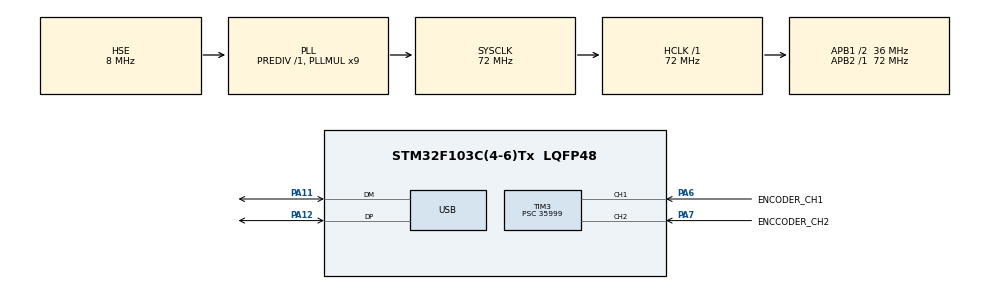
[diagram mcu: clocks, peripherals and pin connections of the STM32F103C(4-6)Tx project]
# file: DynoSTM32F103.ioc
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Mcu.Family=STM32F1
Mcu.Name=STM32F103C(4-6)Tx
Mcu.Package=LQFP48
NVIC.PriorityGroup=NVIC_PRIORITYGROUP_4
NVIC.TIM2_IRQn=true\:0\:0\:false\:true\:true\:3\:true\:true\:true
NVIC.TIM3_IRQn=true\:0\:0\:false\:true\:true\:1\:true\:true\:true
NVIC.USB_LP_CAN1_RX0_IRQn=true\:0\:0\:false\:true\:true\:2\:true\:true\:true
PA11.Mode=Device
PA11.Signal=USB_DM
PA12.Mode=Device
PA12.Signal=USB_DP
PA6.GPIO_Label=ENCODER_CH1
PA6.Signal=S_TIM3_CH1
PA7.GPIO_Label=ENCCODER_CH2
PA7.Signal=S_TIM3_CH2
PD0-OSC_IN.Mode=HSE-External-Oscillator
PD0-OSC_IN.Signal=RCC_OSC_IN
PD1-OSC_OUT.Mode=HSE-External-Oscillator
PD1-OSC_OUT.Signal=RCC_OSC_OUT
ProjectManager.HeapSize=0x200
ProjectManager.StackSize=0x400
ProjectManager.TargetToolchain=STM32CubeIDE
RCC.AHBFreq_Value=72000000
RCC.APB1CLKDivider=RCC_HCLK_DIV2
RCC.APB1Freq_Value=36000000
RCC.APB1TimFreq_Value=72000000
RCC.APB2Freq_Value=72000000
RCC.APB2TimFreq_Value=72000000
RCC.HCLKFreq_Value=72000000
RCC.PLLMUL=RCC_PLL_MUL9
RCC.SYSCLKFreq_VALUE=72000000
RCC.SYSCLKSource=RCC_SYSCLKSOURCE_PLLCLK
RCC.USBFreq_Value=48000000
RCC.USBPrescaler=RCC_USBCLKSOURCE_PLL_DIV1_5
SH.S_TIM3_CH1.0=TIM3_CH1,Encoder_Interface
SH.S_TIM3_CH2.0=TIM3_CH2,Encoder_Interface
TIM2.Period=999
TIM2.Prescaler=35999
TIM3.AutoReloadPreload=TIM_AUTORELOAD_PRELOAD_DISABLE
TIM3.IC1Prescaler=TIM_ICPSC_DIV1
TIM3.Period=3999
TIM3.Prescaler=35999
USB_DEVICE.APP_RX_DATA_SIZE=512
USB_DEVICE.APP_TX_DATA_SIZE=512
USB_DEVICE.CLASS_NAME_FS=CDC
USB_DEVICE.CONFIGURATION_STRING_CDC_FS=CDC_Config
USB_DEVICE.INTERFACE_STRING_CDC_FS=CDC_Interface
USB_DEVICE.MANUFACTURER_STRING=PolijeTI
USB_DEVICE.PID_CDC_FS=1406
USB_DEVICE.PRODUCT_STRING_CDC_FS=DynoTest_Polije
USB_DEVICE.VID=3220
USB_DEVICE.VirtualMode=Cdc
USB_DEVICE.VirtualModeFS=Cdc_FS
VP_TIM2_VS_ClockSourceINT.Mode=Internal
VP_USB_DEVICE_VS_USB_DEVICE_CDC_FS.Mode=CDC_FS
board=custom

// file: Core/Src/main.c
/* USER CODE BEGIN Header */
/**
 ******************************************************************************
 * @file           : main.c
 * @brief          : Main program body
 ******************************************************************************
 * @attention
 *
 * Copyright (c) 2023 STMicroelectronics.
 * All rights reserved.
 *
 * This software is licensed under terms that can be found in the LICENSE file
 * in the root directory of this software component.
 * If no LICENSE file comes with this software, it is provided AS-IS.
 *
 ******************************************************************************
 */
/* USER CODE END Header */
#include <gpio.h>
#include <main.h>
#include <tim.h>
#include <usb_device.h>

void SystemClock_Config(void);
static void MX_NVIC_Init(void);

int main(void) {

  /* MCU Configuration--------------------------------------------------------*/

  /* Reset of all peripherals, Initializes the Flash interface and the Systick.
   */
  HAL_Init();

  /* Configure the system clock */
  SystemClock_Config();

  /* Initialize all configured peripherals */
  MX_GPIO_Init();
  MX_TIM2_Init();
  MX_TIM3_Init();
  MX_USB_DEVICE_Init();

  /* Initialize interrupts */
  MX_NVIC_Init();

  /* Infinite loop */
  while (1) {

  }
}

void SystemClock_Config(void) {
  RCC_OscInitTypeDef RCC_OscInitStruct = {0};
  RCC_ClkInitTypeDef RCC_ClkInitStruct = {0};
  RCC_PeriphCLKInitTypeDef PeriphClkInit = {0};

  /** Initializes the RCC Oscillators according to the specified parameters
   * in the RCC_OscInitTypeDef structure.
   */
  RCC_OscInitStruct.OscillatorType = RCC_OSCILLATORTYPE_HSE;
  RCC_OscInitStruct.HSEState = RCC_HSE_ON;
  RCC_OscInitStruct.HSEPredivValue = RCC_HSE_PREDIV_DIV1;
  RCC_OscInitStruct.HSIState = RCC_HSI_ON;
  RCC_OscInitStruct.PLL.PLLState = RCC_PLL_ON;
  RCC_OscInitStruct.PLL.PLLSource = RCC_PLLSOURCE_HSE;
  RCC_OscInitStruct.PLL.PLLMUL = RCC_PLL_MUL9;
  if (HAL_RCC_OscConfig(&RCC_OscInitStruct) != HAL_OK) {
    Error_Handler();
  }

  /** Initializes the CPU, AHB and APB buses clocks
   */
  RCC_ClkInitStruct.ClockType = RCC_CLOCKTYPE_HCLK | RCC_CLOCKTYPE_SYSCLK |
                                RCC_CLOCKTYPE_PCLK1 | RCC_CLOCKTYPE_PCLK2;
  RCC_ClkInitStruct.SYSCLKSource = RCC_SYSCLKSOURCE_PLLCLK;
  RCC_ClkInitStruct.AHBCLKDivider = RCC_SYSCLK_DIV1;
  RCC_ClkInitStruct.APB1CLKDivider = RCC_HCLK_DIV2;
  RCC_ClkInitStruct.APB2CLKDivider = RCC_HCLK_DIV1;

  if (HAL_RCC_ClockConfig(&RCC_ClkInitStruct, FLASH_LATENCY_2) != HAL_OK) {
    Error_Handler();
  }
  PeriphClkInit.PeriphClockSelection = RCC_PERIPHCLK_USB;
  PeriphClkInit.UsbClockSelection = RCC_USBCLKSOURCE_PLL_DIV1_5;
  if (HAL_RCCEx_PeriphCLKConfig(&PeriphClkInit) != HAL_OK) {
    Error_Handler();
  }
}

/**
 * @brief NVIC Configuration.
 * @retval None
 */
static void MX_NVIC_Init(void) {
  /* TIM3_IRQn interrupt configuration */
  HAL_NVIC_SetPriority(TIM3_IRQn, 0, 0);
  HAL_NVIC_EnableIRQ(TIM3_IRQn);
  /* USB_LP_CAN1_RX0_IRQn interrupt configuration */
  HAL_NVIC_SetPriority(USB_LP_CAN1_RX0_IRQn, 0, 0);
  HAL_NVIC_EnableIRQ(USB_LP_CAN1_RX0_IRQn);
  /* TIM2_IRQn interrupt configuration */
  HAL_NVIC_SetPriority(TIM2_IRQn, 0, 0);
  HAL_NVIC_EnableIRQ(TIM2_IRQn);
}

/* USER CODE BEGIN 4 */
void MX_USB_Receiver_Irq(uint8_t *Buf, uint32_t *Len) {
}

/* USER CODE END 4 */

void Error_Handler(void) {
  __disable_irq();
  while (1) {
  }
}

#ifdef USE_FULL_ASSERT
/**
 * @brief  Reports the name of the source file and the source line number
 *         where the assert_param error has occurred.
 * @param  file: pointer to the source file name
 * @param  line: assert_param error line source number
 * @retval None
 */
void assert_failed(uint8_t *file, uint32_t line) {
  /* USER CODE BEGIN 6 */
  /* User can add his own implementation to report the file name and line
     number, ex: printf("Wrong parameters value: file %s on line %d\r\n", file,
     line) */
  /* USER CODE END 6 */
}
#endif /* USE_FULL_ASSERT */
